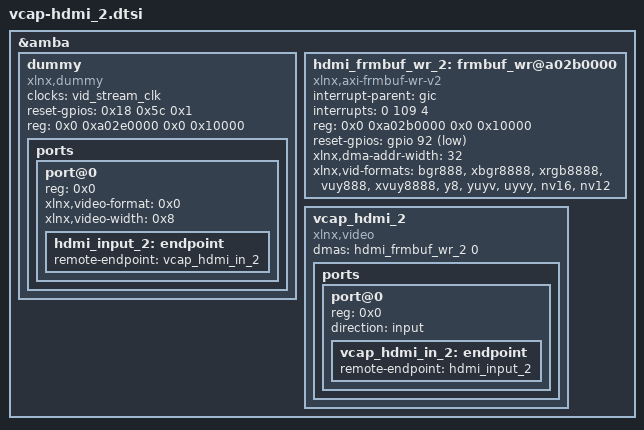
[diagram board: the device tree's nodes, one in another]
&amba {

	dummy {
		compatible = "xlnx,dummy";
		#address-cells = <0x1>;
		#size-cells = <0x0>;
		clocks = <&vid_stream_clk>;
		reset-gpios = <0x18 0x5c 0x1>;
		reg = <0x0 0xa02e0000 0x0 0x10000>;
            
		ports {
			#address-cells = <0x1>;
                	#size-cells = <0x0>;

	                port@0 {
				reg = <0x0>;
				xlnx,video-format = <0x0>;
				xlnx,video-width = <0x8>;

				hdmi_input_2:endpoint {
					remote-endpoint = <&vcap_hdmi_in_2>;
				};
			};
		};
	};

	hdmi_frmbuf_wr_2: frmbuf_wr@a02b0000 {
		compatible = "xlnx,axi-frmbuf-wr-v2";
		#dma-cells = <1>;
		interrupt-parent = <&gic>;
		interrupts = <0 109 4>;
		reg = <0x0 0xa02b0000 0x0 0x10000>;
		reset-gpios = <&gpio 92 1>;
		xlnx,dma-addr-width = <32>;
		xlnx,vid-formats = "bgr888","xbgr8888","xrgb8888","vuy888","xvuy8888","y8","yuyv","uyvy","nv16","nv12";
	};

	vcap_hdmi_2 {
		compatible = "xlnx,video";
		dmas = <&hdmi_frmbuf_wr_2 0>;
		dma-names = "port0";

		ports {
			#address-cells = <0x1>;
			#size-cells = <0x0>;

			port@0 {
				reg = <0x0>;
				direction = "input";

				vcap_hdmi_in_2:endpoint {
					remote-endpoint = <&hdmi_input_2>;
				};
			};
		};
	};

};
